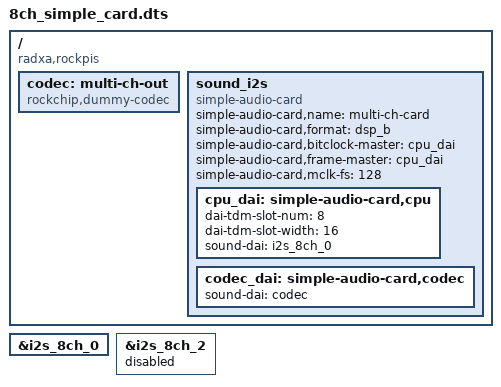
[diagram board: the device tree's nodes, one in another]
// Definitions for 8-ch-output
/dts-v1/;
/plugin/;

/ {
        compatible = "radxa,rockpis", "rockchip,rk3308";

        fragment@0 {
                target = <&i2s_8ch_0>;
                
                __overlay__ {
                        #sound-dai-cells = <0>;
                        status = "okay";
                        };
               };
               
        fragment@1 {
                target = <&i2s_8ch_2>;
                
                __overlay__ {
                        #sound-dai-cells = <0>;
                        status = "disabled";
                        };
               };

        fragment@2 {
                target-path = "/";
                
                __overlay__ {
                        codec: multi-ch-out {
                                #sound-dai-cells = <0>;
                                compatible = "rockchip,dummy-codec";
                                status = "okay";
                                };
                        
                        sound_i2s {
                                simple-audio-card,name = "multi-ch-card";
                                compatible = "simple-audio-card";
                                simple-audio-card,format = "dsp_b";
                                simple-audio-card,bitclock-master = <&cpu_dai>;
                                simple-audio-card,frame-master = <&cpu_dai>;
                                simple-audio-card,mclk-fs = <128>;
                                status = "okay";
                                
                                cpu_dai: simple-audio-card,cpu {
                                dai-tdm-slot-num = <8>;
                                dai-tdm-slot-width = <16>;
                                sound-dai = <&i2s_8ch_0>;
                                };
                                
                                codec_dai: simple-audio-card,codec {
                                sound-dai = <&codec>;
                                };
                         };
                };
        };
};
